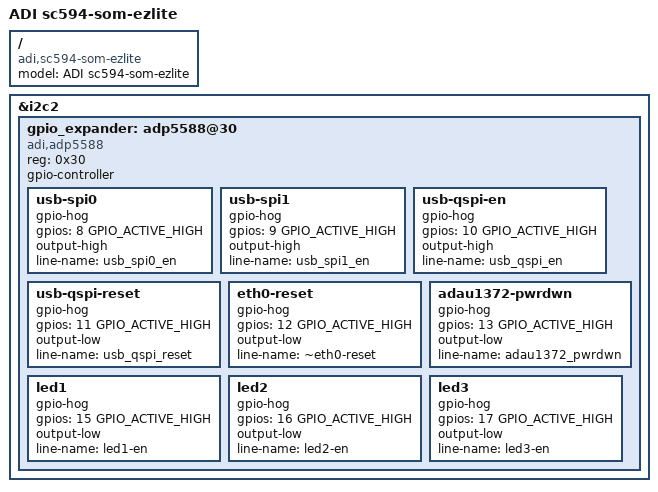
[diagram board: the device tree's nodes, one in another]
// SPDX-License-Identifier: GPL-2.0-or-later
/*
 * (C) Copyright 2022 - Analog Devices, Inc.
 *
 * Written and/or maintained by Timesys Corporation
 *
 * Contact: Nathan Barrett-Morrison <nathan.morrison@timesys.com>
 * Contact: Greg Malysa <greg.malysa@timesys.com>
 */

/dts-v1/;

#include "sc594-som.dtsi"

/ {
	model = "ADI sc594-som-ezlite";
	compatible = "adi,sc594-som-ezlite", "adi,sc59x";
};

&i2c2{
	gpio_expander: adp5588@30 {
		compatible = "adi,adp5588";
		reg = <0x30>;
		gpio-controller;
		#gpio-cells = <2>;
		bootph-all;

		usb-spi0 {
			gpio-hog;
			gpios = <8 GPIO_ACTIVE_HIGH>;
			output-high;
			line-name = "usb_spi0_en";
			bootph-all;
		};

		usb-spi1 {
			gpio-hog;
			gpios = <9 GPIO_ACTIVE_HIGH>;
			output-high;
			line-name = "usb_spi1_en";
			bootph-all;
		};

		usb-qspi-en {
			gpio-hog;
			gpios = <10 GPIO_ACTIVE_HIGH>;
			output-high;
			line-name = "usb_qspi_en";
			bootph-all;
		};

		usb-qspi-reset {
			gpio-hog;
			gpios = <11 GPIO_ACTIVE_HIGH>;
			output-low;
			line-name = "usb_qspi_reset";
			bootph-all;
		};

		eth0-reset {
			gpio-hog;
			gpios = <12 GPIO_ACTIVE_HIGH>;
			output-low;
			line-name = "~eth0-reset";
			bootph-all;
		};

		adau1372-pwrdwn {
			gpio-hog;
			gpios = <13 GPIO_ACTIVE_HIGH>;
			output-low;
			line-name = "adau1372_pwrdwn";
			bootph-all;
		};

		led1 {
			gpio-hog;
			gpios = <15 GPIO_ACTIVE_HIGH>;
			output-low;
			line-name = "led1-en";
			bootph-all;
		};

		led2 {
			gpio-hog;
			gpios = <16 GPIO_ACTIVE_HIGH>;
			output-low;
			line-name = "led2-en";
			bootph-all;
		};

		led3 {
			gpio-hog;
			gpios = <17 GPIO_ACTIVE_HIGH>;
			output-low;
			line-name = "led3-en";
			bootph-all;
		};

	};
};
